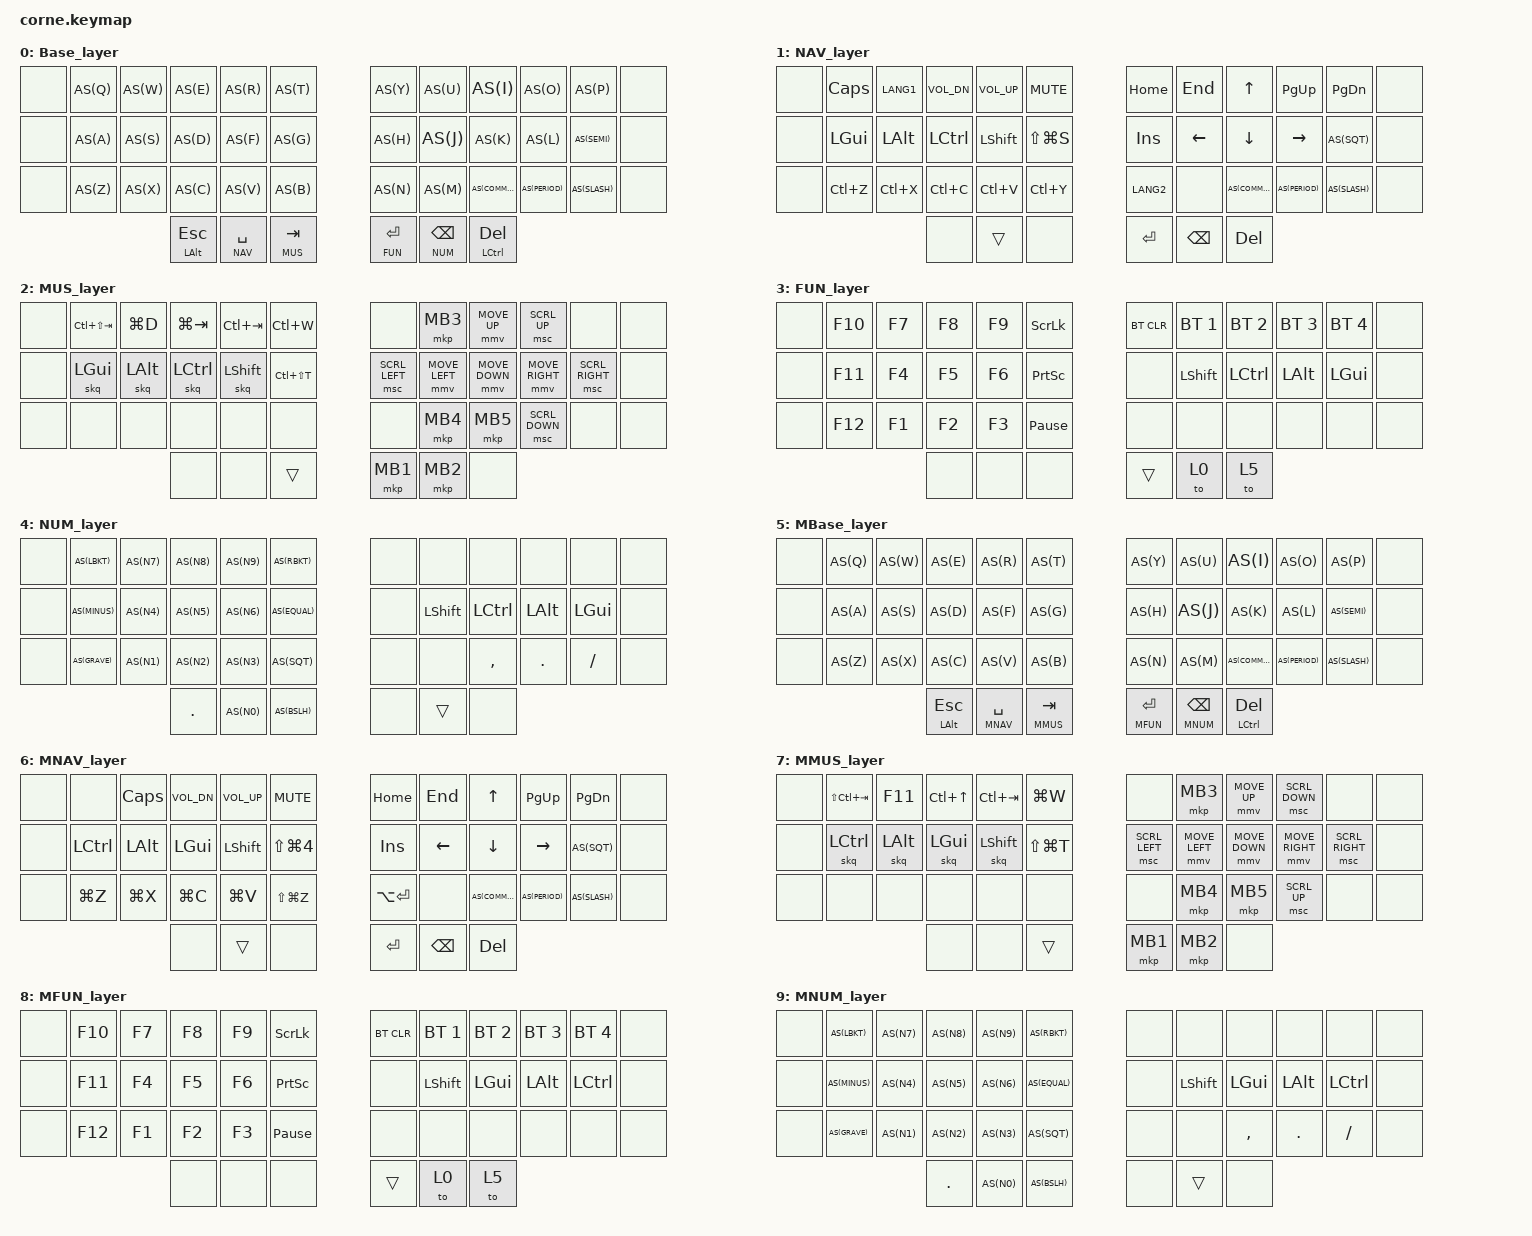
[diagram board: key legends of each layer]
/*
 * Copyright (c) 2020 The ZMK Contributors
 *
 * SPDX-License-Identifier: MIT
 */

#include <behaviors.dtsi>
#include <dt-bindings/zmk/keys.h>
#include <dt-bindings/zmk/bt.h>
#include <dt-bindings/zmk/mouse.h>
#include <dt-bindings/zmk/ext_power.h>
#include "mouse.dtsi"
#define AS(keycode) &as LS(keycode) keycode  


#define BASE 0
#define NAV 1
#define MUS 2
#define FUN 3
#define NUM 4
#define MBASE 5
#define MNAV 6
#define MMUS 7
#define MFUN 8
#define MNUM 9

#define XXX &none
#define TRN &trans

/ {
behaviors {
        /*
        bhm: balanced_homerow_mods {
                compatible = "zmk,behavior-hold-tap";
                label = "HOMEROW_MODS";
                #binding-cells = <2>;
                flavor = "balanced";
                tapping-term-ms = <280>;
                quick-tap-ms = <175>;                // repeat on tap-into-hold
                require-prior-idle-ms = <150>;
                bindings = <&kp>, <&kp>;
                hold-trigger-on-release;             // delay positional check until key-release
        };
        */
        bhm: balanced_homerow_mods {
            compatible = "zmk,behavior-hold-tap";
            #binding-cells = <2>;
            tapping-term-ms = <200>;    // <---[[moderate duration]]
            quick-tap-ms = <0>;
            flavor = "balanced";
            bindings = <&kp>, <&kp>;
        };
        skq: sticky_key_quick_release {
            compatible = "zmk,behavior-sticky-key";
            #binding-cells = <1>;
            bindings = <&kp>;
            release-after-ms = <1000>;
            quick-release;
            ignore-modifiers;
        };
        as: auto_shift {
            compatible = "zmk,behavior-hold-tap";
            #binding-cells = <2>;
            tapping_term_ms = <185>;
            quick_tap_ms = <0>;
            flavor = "tap-preferred";
            bindings = <&kp>, <&kp>;
        };
};
        keymap {
                compatible = "zmk,keymap";

                Base_layer {
// -----------------------------------------------------------------------------------------
// |     |  Q  |  W  |  E  |  R  |  T  |   |  Y  |  U   |  I  |  O  |  P  |     |
// |     |  A  |  S  |  D  |  F  |  G  |   |  H  |  J   |  K  |  L  |  ;  |     |
// |     |  Z  |  X  |  C  |  V  |  B  |   |  N  |  M   |  ,  |  .  |  /  |     |
//       | ESC | SPC(NAV)  | TAB(MUS)  |   |  RET(SYM)  | BCK(NUM)  | DEL(FUN) |
                        bindings = <
//╭─────┬────────┬───────┬─────────┬───────────────┬─────────────╮ ╭─────────────┬──────────────┬───────────┬────────────┬───────────┬─────╮
    XXX   AS(Q)    AS(W)   AS(E)     AS(R)           AS(T)           AS(Y)         AS(U)          AS(I)       AS(O)        AS(P)       XXX   
//├─────┼────────┼───────┼─────────┼───────────────┼─────────────┤ ├─────────────┼──────────────┼───────────┼────────────┼───────────┼─────┤
    XXX   AS(A)    AS(S)   AS(D)     AS(F)           AS(G)           AS(H)         AS(J)          AS(K)       AS(L)        AS(SEMI)    XXX
//├─────┼────────┼───────┼─────────┼───────────────┼─────────────┤ ├─────────────┼──────────────┼───────────┼────────────┼───────────┼─────┤
    XXX   AS(Z)    AS(X)   AS(C)     AS(V)           AS(B)           AS(N)         AS(M)          AS(COMMA)   AS(PERIOD)   AS(SLASH)   XXX     
//╰─────┴────────┴───────┼─────────┼───────────────┼─────────────┤ ├─────────────┼──────────────┼───────────┼────────────┴───────────┴─────╯ 
                           &bhm LALT ESC   &lt NAV SPACE   &lt MUS TAB     &lt FUN RET   &lt NUM BSPC   &bhm LCTRL DEL                                               
//                       ╰─────────┴───────────────┴─────────────╯ ╰─────────────┴──────────────┴───────────╯   
                        >;
                };

                NAV_layer {
// -----------------------------------------------------------------------------------------
// |     | CAP | HAN | VL- | VL+ | MUT |   | HOME| END |  UP |PG_UP|PG_DN|     |
// |     | GUI | ALT | CTL | SFT |LSLGS|   | INS | LEFT| DOWN|RIGHT|  '  |     |
// |     |CTL_Z|CTL_X|CTL_C|CTL_V|CTL_Y|   |HANJA|     |  ,  |  .  |  /  |     |
//                   |     | TRN |     |   | RET | BSPC| DEL |
                        bindings = <
//╭─────┬────────────┬──────────────┬──────────────┬───────────┬──────────────╮ ╭───────────┬──────────┬──────────┬───────────┬─────────┬─────╮
    XXX   &kp CAPS     &kp LANG1     &kp C_VOL_DN   &kp C_VOL_UP &kp C_MUTE       &kp HOME    &kp END    &kp UP     &kp PG_UP  &kp PG_DN  XXX   
//├─────┼────────────┼──────────────┼──────────────┼───────────┼──────────────┤ ├───────────┼──────────┼──────────┼───────────┼─────────┼─────┤
    XXX   &kp LGUI     &kp LALT       &kp LCTRL      &kp LSHFT   &kp LS(LG(S))   &kp INS      &kp LEFT   &kp DOWN   &kp RIGHT   AS(SQT)   XXX    
//├─────┼────────────┼──────────────┼──────────────┼───────────┼──────────────┤ ├───────────┼──────────┼──────────┼───────────┼─────────┼─────┤
    XXX   &kp LC(Z)    &kp LC(X)      &kp LC(C)      &kp LC(V)   &kp LC(Y)        &kp LANG2   XXX       AS(COMMA)  AS(PERIOD)  AS(SLASH)  XXX   
//╰─────┴────────────┴──────────────┼──────────────┼───────────┼──────────────┤ ├───────────┼──────────┼──────────┼───────────┴─────────┴─────╯ 
                                      XXX            TRN         XXX              &kp RET     &kp BSPC   &kp DEL                                           
//                                  ╰──────────────┴───────────┴──────────────╯ ╰───────────┴──────────┴──────────╯  
                        >;
                };

               MUS_layer {
// -----------------------------------------------------------------------------------------
// |     |BCKTB|BSSCR|WINTB|NXTTB|DELTB|   |     | MB3 | M_U | MSU |     |     |
// |     | GUI | ALT | CTL | SFT |RE_TB|   | MSL | M_L | M_D | M_R | MSR |     |
// |     |     |     |     |     |     |   |     | MB4 | MB5 | MSD |     |     |
//                   |     |     | TRN |   | MB1 | MB2 |     |
                        bindings = <
//╭─────┬──────────┬──────────┬───────────┬───────────┬─────╮ ╭──────────────────┬────────────────┬────────────────┬──────────────────┬───────────────────┬─────╮
    XXX   &kp LC(LS(TAB))  &kp LG(D)  &kp LG(TAB)  &kp LC(TAB)  &kp LC(W)   XXX    &mkp MB3         &mmv MOVE_UP       &msc SCRL_UP     XXX              XXX   
//├─────┼──────────┼──────────┼───────────┼───────────┼─────┤ ├──────────────────┼────────────────┼────────────────┼──────────────────┼───────────────────┼─────┤
    XXX   &skq LGUI   &skq LALT   &skq LCTRL  &skq LSHFT   &kp LC(LS(T))   &msc SCRL_LEFT   &mmv MOVE_LEFT   &mmv MOVE_DOWN   &mmv MOVE_RIGHT    &msc SCRL_RIGHT   XXX 
//├─────┼──────────┼──────────┼───────────┼───────────┼─────┤ ├──────────────────┼────────────────┼────────────────┼──────────────────┼───────────────────┼─────┤
    XXX   XXX        XXX        XXX         XXX         XXX     XXX                &mkp MB4         &mkp MB5         &msc SCRL_DOWN   XXX                 XXX 
//╰─────┴──────────┴──────────┼───────────┼───────────┼─────┤ ├──────────────────┼────────────────┼────────────────┼──────────────────┴───────────────────┴─────╯ 
                                XXX         XXX         TRN     &mkp MB1           &mkp MB2         XXX                                      
//                            ╰───────────┴───────────┴─────╯ ╰──────────────────┴────────────────┴────────────────╯ 
                        >;
                };

                FUN_layer {
// -----------------------------------------------------------------------------------------
// |     | F10 |  F7 |  F8 |  F9 | SLCK|   | CLR | BT1 | BT2 | BT3 | BT4 |     |
// |     | F11 |  F4 |  F5 |  F6 |PSCRN|   |     | SFT | CTL | ALT | GUI |     |
// |     | F12 |  F1 |  F2 |  F3 |PAUSE|   |     |     |     |     |     |     |
//                   |     |     |     |   | TRN | WIN | MAC |
                        bindings = <
//╭─────┬─────────┬────────┬────────┬────────┬─────────────────╮ ╭─────┬───────────┬───────────┬──────────┬──────────┬─────╮
    XXX   &kp F10   &kp F7   &kp F8   &kp F9   &kp SLCK            &bt BT_CLR  &bt BT_SEL 1   &bt BT_SEL 2   &bt BT_SEL 3   &bt BT_SEL 4   XXX
//├─────┼─────────┼────────┼────────┼────────┼─────────────────┤ ├─────┼───────────┼───────────┼──────────┼──────────┼─────┤
    XXX   &kp F11   &kp F4   &kp F5   &kp F6   &kp PSCRN           XXX   &kp LSHFT   &kp LCTRL   &kp LALT   &kp LGUI   XXX 
//├─────┼─────────┼────────┼────────┼────────┼─────────────────┤ ├─────┼───────────┼───────────┼──────────┼──────────┼─────┤
    XXX   &kp F12   &kp F1   &kp F2   &kp F3   &kp PAUSE_BREAK     XXX   XXX         XXX         XXX        XXX        XXX  
//╰─────┴─────────┴────────┼────────┼────────┼─────────────────┤ ├─────┼───────────┼───────────┼──────────┴──────────┴─────╯ 
                             XXX      XXX      XXX                 TRN   &to 0       &to 5                                                 
//                         ╰────────┴────────┴─────────────────╯ ╰─────┴───────────┴───────────╯ 
                        >;
                };

                NUM_layer {
// -----------------------------------------------------------------------------------------
// |     |  [  |  7  |  8  |  9  |  ]  |   |     |     |     |     |     |     |
// |     |  -  |  4  |  5  |  6  |  =  |   |     | SFT | CTL | ALT | GUI |     |
// |     |  `  |  1  |  2  |  3  |  '  |   |     |     |  ,  |  .  |  /  |     |
//                   |  .  |  0  |  \  |   |     | TRN |     |
                        bindings = <
//╭─────┬───────────┬────────┬─────────┬────────┬───────────╮ ╭─────┬───────────┬───────────┬──────────┬──────────┬─────╮
    XXX   AS(LBKT)    AS(N7)   AS(N8)    AS(N9)   AS(RBKT)      XXX   XXX         XXX         XXX        XXX        XXX 
//├─────┼───────────┼────────┼─────────┼────────┼───────────┤ ├─────┼───────────┼───────────┼──────────┼──────────┼─────┤
    XXX   AS(MINUS)   AS(N4)   AS(N5)   AS(N6)    AS(EQUAL)     XXX   &kp LSHFT  &kp LCTRL  &kp LALT  &kp LGUI  XXX 
//├─────┼───────────┼────────┼─────────┼────────┼───────────┤ ├─────┼───────────┼───────────┼──────────┼──────────┼─────┤
    XXX   AS(GRAVE)   AS(N1)   AS(N2)    AS(N3)   AS(SQT)       XXX   XXX         &kp COMMA  &kp PERIOD  &kp SLASH  XXX    
//╰─────┴───────────┴────────┼─────────┼────────┼───────────┤ ├─────┼───────────┼───────────┼──────────┴──────────┴─────╯ 
                               &kp DOT   AS(N0)   AS(BSLH)      XXX   TRN         XXX                                            
//                           ╰─────────┴────────┴───────────╯ ╰─────┴───────────┴───────────╯ 

                        >;
                };
        
                MBase_layer {
// -----------------------------------------------------------------------------------------
// |     |  Q  |  W  |  E  |  R  |  T  |   |  Y  |  U   |  I  |  O  |  P  |     |
// |     |  A  |  S  |  D  |  F  |  G  |   |  H  |  J   |  K  |  L  |  ;  |     |
// |     |  Z  |  X  |  C  |  V  |  B  |   |  N  |  M   |  ,  |  .  |  /  |     |
//       | ESC | SPC(MNAV) | TAB(MMUS) |   |  RET(MFUN) | BCK(MNUM) | DEL |
                        bindings = <
//╭─────┬────────┬───────┬─────────┬────────────────┬──────────────╮ ╭──────────────┬───────────────┬───────────┬────────────┬───────────┬─────╮
    XXX   AS(Q)    AS(W)   AS(E)     AS(R)            AS(T)            AS(Y)          AS(U)           AS(I)       AS(O)        AS(P)       XXX   
//├─────┼────────┼───────┼─────────┼────────────────┼──────────────┤ ├──────────────┼───────────────┼───────────┼────────────┼───────────┼─────┤
    XXX   AS(A)    AS(S)   AS(D)     AS(F)            AS(G)            AS(H)          AS(J)           AS(K)       AS(L)        AS(SEMI)    XXX
//├─────┼────────┼───────┼─────────┼────────────────┼──────────────┤ ├──────────────┼───────────────┼───────────┼────────────┼───────────┼─────┤
    XXX   AS(Z)    AS(X)   AS(C)     AS(V)            AS(B)            AS(N)          AS(M)           AS(COMMA)   AS(PERIOD)   AS(SLASH)   XXX     
//╰─────┴────────┴───────┼─────────┼────────────────┼──────────────┤ ├──────────────┼───────────────┼───────────┼────────────┴───────────┴─────╯ 
                           &bhm LALT ESC   &lt MNAV SPACE   &lt MMUS TAB     &lt MFUN RET   &lt MNUM BSPC   &bhm LCTRL DEL                                               
//                       ╰─────────┴────────────────┴──────────────╯ ╰──────────────┴───────────────┴───────────╯   
                        >;
                };

                MNAV_layer {
// -----------------------------------------------------------------------------------------
// |     |     | HAN | VL- | VL+ | MUT |   | HOME| END |  UP |PG_UP|PG_DN|     |
// |     | GUI | ALT | CTL | SFT |LSLGS|   | INS | LEFT| DOWN|RIGHT|  '  |     |
// |     |GUI_Z|GUI_X|GUI_C|GUI_V|LSLG4|   |HANJA|     |  ,  |  .  |  /  |     |
//                   |     | TRN |     |   | RET | BSPC| DEL |
                        bindings = <
//╭─────┬────────────┬──────────────┬──────────────┬───────────────┬───────────────╮ ╭────────────┬──────────┬──────────┬───────────┬─────────┬─────╮
    XXX   XXX          &kp CAPS       &kp C_VOL_DN   &kp C_VOL_UP    &kp C_MUTE        &kp HOME     &kp END    &kp UP     &kp PG_UP   &kp PG_DN  XXX  
//├─────┼────────────┼──────────────┼──────────────┼───────────────┼───────────────┤ ├────────────┼──────────┼──────────┼───────────┼─────────┼─────┤
    XXX   &kp LCTRL   &kp LALT    &kp LGUI   &kp LSHFT      &kp LS(LG(N4))    &kp INS      &kp LEFT   &kp DOWN   &kp RIGHT   AS(SQT)   XXX  
//├─────┼────────────┼──────────────┼──────────────┼───────────────┼───────────────┤ ├────────────┼──────────┼──────────┼───────────┼─────────┼─────┤
    XXX   &kp LG(Z)    &kp LG(X)      &kp LG(C)      &kp LG(V)       &kp LS(LG(Z))     &kp LA(RET)  XXX       AS(COMMA)  AS(PERIOD)  AS(SLASH)  XXX   
//╰─────┴────────────┴──────────────┼──────────────┼───────────────┼───────────────┤ ├────────────┼──────────┼──────────┼───────────┴─────────┴─────╯ 
                                      XXX            TRN             XXX               &kp RET      &kp BSPC   &kp DEL                                           
//                                  ╰──────────────┴───────────────┴───────────────╯ ╰────────────┴──────────┴──────────╯  
                        >;
                };

               MMUS_layer {
// -----------------------------------------------------------------------------------------
// |     |SCTAB| F11 | ALTB|LCTAB|     |   |     | MB3 | M_U | MSU |     |     |
// |     | CTL | ALT | GUI | SFT |     |   | MSL | M_L | M_D | M_R | MSR |     |
// |     |     |     |     |     |     |   |     | MB4 | MB5 | MSD |     |     |
//                   |     |     | TRN |   | MB1 | MB2 |     |
                        bindings = <
//╭─────┬───────────┬───────────┬──────────┬───────────┬─────╮ ╭──────────────────┬────────────────┬────────────────┬──────────────────┬───────────────────┬─────╮
    XXX   &kp LS(LC(TAB))  &kp F11  &kp LC(UP)  &kp LC(TAB)   &kp LG(W)   XXX                &mkp MB3         &mmv MOVE_UP     &msc SCRL_DOWN     XXX                 XXX 
//├─────┼───────────┼───────────┼──────────┼───────────┼─────┤ ├──────────────────┼────────────────┼────────────────┼──────────────────┼───────────────────┼─────┤
    XXX   &skq LCTRL  &skq LALT   &skq LGUI  &skq LSHFT  &kp LS(LG(T))   &msc SCRL_LEFT   &mmv MOVE_LEFT   &mmv MOVE_DOWN   &mmv MOVE_RIGHT    &msc SCRL_RIGHT   XXX 
//├─────┼───────────┼───────────┼──────────┼───────────┼─────┤ ├──────────────────┼────────────────┼────────────────┼──────────────────┼───────────────────┼─────┤
    XXX   XXX         XXX         XXX        XXX         XXX     XXX                &mkp MB4         &mkp MB5         &msc SCRL_UP   XXX                 XXX 
//╰─────┴───────────┴───────────┼──────────┼───────────┼─────┤ ├──────────────────┼────────────────┼────────────────┼──────────────────┴───────────────────┴─────╯ 
                                  XXX        XXX         TRN     &mkp MB1           &mkp MB2         XXX                                      
//                              ╰──────────┴───────────┴─────╯ ╰──────────────────┴────────────────┴────────────────╯ 
                        >;
                };

                MFUN_layer {
// -----------------------------------------------------------------------------------------
// |     | F10 |  F7 |  F8 |  F9 |PAUSE|   | CLR | BT1 | BT2 | BT# | BT4 |     |
// |     | F11 |  F4 |  F5 |  F6 |PSCRN|   |     | SFT | GUI | ALT | CTL |     |
// |     | F12 |  F1 |  F2 |  F3 | SLCK|   |     |     |     |     |     |     |
//                   |     |     |     |   | TRN | WIN | MAC |
                        bindings = <
//╭─────┬─────────┬────────┬────────┬────────┬─────────────────╮ ╭─────┬───────────┬──────────┬──────────┬───────────┬─────╮
    XXX   &kp F10   &kp F7   &kp F8   &kp F9   &kp SLCK            &bt BT_CLR  &bt BT_SEL 1   &bt BT_SEL 2   &bt BT_SEL 3   &bt BT_SEL 4  XXX 
//├─────┼─────────┼────────┼────────┼────────┼─────────────────┤ ├─────┼───────────┼──────────┼──────────┼───────────┼─────┤
    XXX   &kp F11   &kp F4   &kp F5   &kp F6   &kp PSCRN           XXX   &kp LSHFT   &kp LGUI   &kp LALT   &kp LCTRL   XXX 
//├─────┼─────────┼────────┼────────┼────────┼─────────────────┤ ├─────┼───────────┼──────────┼──────────┼───────────┼─────┤
    XXX   &kp F12   &kp F1   &kp F2   &kp F3   &kp PAUSE_BREAK     XXX   XXX         XXX        XXX        XXX         XXX  
//╰─────┴─────────┴────────┼────────┼────────┼─────────────────┤ ├─────┼───────────┼──────────┼──────────┴───────────┴─────╯ 
                             XXX      XXX      XXX                 TRN   &to 0      &to 5                                                  
//                         ╰────────┴────────┴─────────────────╯ ╰─────┴───────────┴──────────╯ 
                        >;
                };

                MNUM_layer {
// -----------------------------------------------------------------------------------------
// |     |  [  |  7  |  8  |  9  |  ]  |   |     |     |     |     |     |     |
// |     |  -  |  4  |  5  |  6  |  =  |   |     | SFT | GUI | ALT | CTL |     |
// |     |  `  |  1  |  2  |  3  |  '  |   |     |     |  ,  |  .  |  /  |     |
//                   |  .  |  0  |  \  |   |     | TRN |     |
                        bindings = <
//╭─────┬───────────┬────────┬─────────┬────────┬───────────╮ ╭─────┬───────────┬──────────┬──────────┬───────────┬─────╮
    XXX   AS(LBKT)    AS(N7)   AS(N8)    AS(N9)   AS(RBKT)      XXX   XXX         XXX        XXX        XXX         XXX 
//├─────┼───────────┼────────┼─────────┼────────┼───────────┤ ├─────┼───────────┼──────────┼──────────┼───────────┼─────┤
    XXX   AS(MINUS)   AS(N4)   AS(N5)   AS(N6)    AS(EQUAL)     XXX   &kp LSHFT  &kp LGUI  &kp LALT  &kp LCTRL      XXX 
//├─────┼───────────┼────────┼─────────┼────────┼───────────┤ ├─────┼───────────┼──────────┼──────────┼───────────┼─────┤
    XXX   AS(GRAVE)   AS(N1)   AS(N2)    AS(N3)   AS(SQT)       XXX   XXX         &kp COMMA  &kp PERIOD  &kp SLASH  XXX
//╰─────┴───────────┴────────┼─────────┼────────┼───────────┤ ├─────┼───────────┼──────────┼──────────┴───────────┴─────╯ 
                               &kp DOT   AS(N0)   AS(BSLH)      XXX   TRN         XXX                                            
//                           ╰─────────┴────────┴───────────╯ ╰─────┴───────────┴──────────╯ 
                        >;
                };
        };
};
